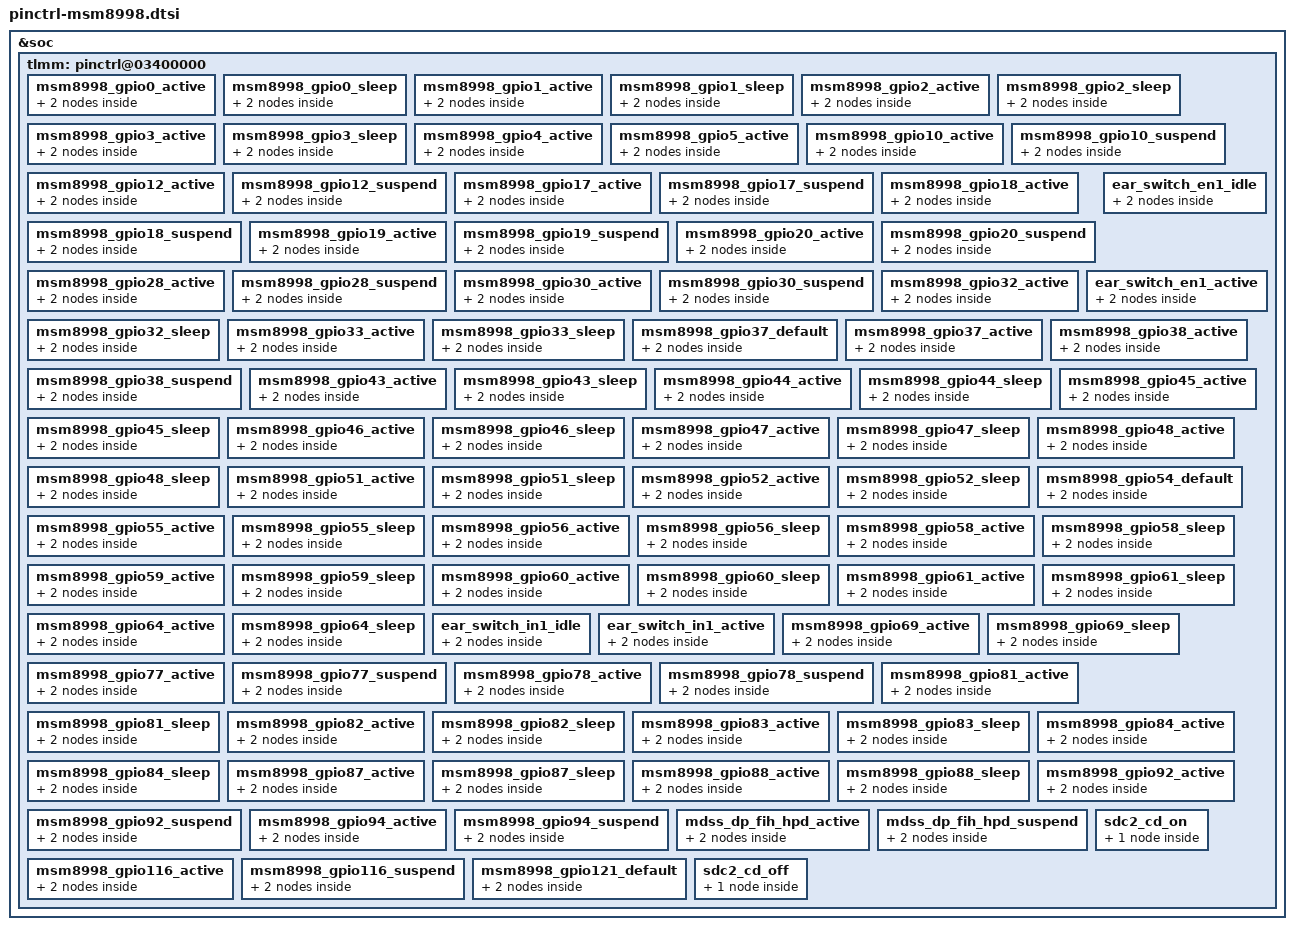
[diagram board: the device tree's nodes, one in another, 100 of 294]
/* Copyright (c) 2015-2016, The Linux Foundation. All rights reserved.
 *
 * This program is free software; you can redistribute it and/or modify
 * it under the terms of the GNU General Public License version 2 and
 * only version 2 as published by the Free Software Foundation.
 *
 * This program is distributed in the hope that it will be useful,
 * but WITHOUT ANY WARRANTY; without even the implied warranty of
 * MERCHANTABILITY or FITNESS FOR A PARTICULAR PURPOSE.  See the
 * GNU General Public License for more details.
 */

&soc {
	tlmm: pinctrl@03400000 {
		/* gpio 0 */ /* NFC_ESE_SPI_MOSI */
		msm8998_gpio0_active: msm8998_gpio0_active {
			mux {
				pins = "gpio0";
				function = "blsp_spi1";
			};

			config {
				pins = "gpio0";
				drive-strength = <6>;
				bias-disable;
			};
		};

		msm8998_gpio0_sleep: msm8998_gpio0_sleep {
			mux {
				pins = "gpio0";
				function = "blsp_spi1";
			};

			config {
				pins = "gpio0";
				drive-strength = <6>;
				bias-disable;
			};
		};

		/* gpio 1 */ /* NFC_ESE_SPI_MISO */
		msm8998_gpio1_active: msm8998_gpio1_active {
			mux {
				pins = "gpio1";
				function = "blsp_spi1";
			};

			config {
				pins = "gpio1";
				drive-strength = <6>;
				bias-disable;
			};
		};

		msm8998_gpio1_sleep: msm8998_gpio1_sleep {
			mux {
				pins = "gpio1";
				function = "blsp_spi1";
			};

			config {
				pins = "gpio1";
				drive-strength = <6>;
				bias-disable;
			};
		};

		/* gpio 2 */ /* NFC_ESE_SPI_CS_N */
		msm8998_gpio2_active: msm8998_gpio2_active {
			mux {
				pins = "gpio2";
				function = "blsp_spi1";
			};

			config {
				pins = "gpio2";
				drive-strength = <6>;
				bias-disable;
			};
		};

		msm8998_gpio2_sleep: msm8998_gpio2_sleep {
			mux {
				pins = "gpio2";
				function = "blsp_spi1";
			};

			config {
				pins = "gpio2";
				drive-strength = <6>;
				bias-disable;
			};
		};

		/* gpio 3 */ /* NFC_ESE_SPI_CLK */
		msm8998_gpio3_active: msm8998_gpio3_active {
			mux {
				pins = "gpio3";
				function = "blsp_spi1";
			};

			config {
				pins = "gpio3";
				drive-strength = <6>;
				bias-disable;
			};
		};

		msm8998_gpio3_sleep: msm8998_gpio3_sleep {
			mux {
				pins = "gpio3";
				function = "blsp_spi1";
			};

			config {
				pins = "gpio3";
				drive-strength = <6>;
				bias-disable;
			};
		};

		/* gpio 4 */ /* DEBUG_UART_TX */
		msm8998_gpio4_active: msm8998_gpio4_active {
			mux {
				pins = "gpio4";
				function = "blsp_uart8_a";
			};

			config {
				pins = "gpio4";
				drive-strength = <2>;
				bias-disable;
			};
		};

		/* gpio 5 */ /* DEBUG_UART_RX */
		msm8998_gpio5_active: msm8998_gpio5_active {
			mux {
				pins = "gpio5";
				function = "blsp_uart8_a";
			};

			config {
				pins = "gpio5";
				drive-strength = <2>;
				bias-disable;
			};
		};

		/* gpio 10 */ /* MDP_VSYNC_P */
		msm8998_gpio10_active: msm8998_gpio10_active {
			mux {
				pins = "gpio10";
				function = "mdp_vsync_a";
			};

			config {
				pins = "gpio10";
				drive-strength = <2>;
				bias-pull-down;
			};
		};

		msm8998_gpio10_suspend: msm8998_gpio10_suspend {
			mux {
				pins = "gpio10";
				function = "mdp_vsync_a";
			};

			config {
				pins = "gpio10";
				drive-strength = <2>;
				bias-pull-down;
			};
		};

		/* gpio 12 */ /* NFC_ENABLE */
		msm8998_gpio12_active: msm8998_gpio12_active {
			mux {
				pins = "gpio12";
				function = "gpio";
			};

			config {
				pins = "gpio12";
				drive-strength = <6>;
				bias-pull-up;
			};
		};

		msm8998_gpio12_suspend: msm8998_gpio12_suspend {
			mux {
				pins = "gpio12";
				function = "gpio";
			};

			config {
				pins = "gpio12";
				drive-strength = <6>;
				bias-disable;
			};
		};

		/* gpio 17 */ /* CCI_I2C_SDA0 */
		msm8998_gpio17_active: msm8998_gpio17_active {
			mux {
				pins = "gpio17";
				function = "cci_i2c";
			};

			config {
				pins = "gpio17";
				drive-strength = <2>;
				bias-pull-up;
			};
		};

		msm8998_gpio17_suspend: msm8998_gpio17_suspend {
			mux {
				pins = "gpio17";
				function = "cci_i2c";
		};

			config {
				pins = "gpio17";
				drive-strength = <2>;
				bias-disable; /* No PULL */
			};
		};

		/* gpio 18 */ /* CCI_I2C_SCL0 */
		msm8998_gpio18_active: msm8998_gpio18_active {
			mux {
				pins = "gpio18";
				function = "cci_i2c";
			};

			config {
				pins = "gpio18";
				drive-strength = <2>;
				bias-pull-up;
			};
		};

		msm8998_gpio18_suspend: msm8998_gpio18_suspend {
			mux {
				pins = "gpio18";
				function = "cci_i2c";
		};

			config {
				pins = "gpio18";
				drive-strength = <2>;
				bias-disable; /* No PULL */
			};
		};

		/* gpio 19 */ /* CCI_I2C_SDA1 */
		msm8998_gpio19_active: msm8998_gpio19_active {
			mux {
				pins = "gpio19";
				function = "cci_i2c";
			};

			config {
				pins = "gpio19";
				drive-strength = <2>;
				bias-pull-up;
			};
		};

		msm8998_gpio19_suspend: msm8998_gpio19_suspend {
			mux {
				pins = "gpio19";
				function = "cci_i2c";
			};

			config {
				pins = "gpio19";
				drive-strength = <2>;
				bias-disable; /* No PULL */
			};
		};

		/* gpio 20 */ /* CCI_I2C_SCL1 */
		msm8998_gpio20_active: msm8998_gpio20_active {
			mux {
				pins = "gpio20";
				function = "cci_i2c";
			};

			config {
				pins = "gpio20";
				drive-strength = <2>;
				bias-pull-up;
			};
		};

		msm8998_gpio20_suspend: msm8998_gpio20_suspend {
			mux {
				pins = "gpio20";
				function = "cci_i2c";
			};

			config {
				pins = "gpio20";
				drive-strength = <2>;
				bias-disable; /* No PULL */
			};
		};

		/* gpio 28 */ /* RCAM1_VCA_EN */
		msm8998_gpio28_active: msm8998_gpio28_active {
			mux {
				pins = "gpio28";
				function = "gpio";
			};

			config {
				pins = "gpio28";
				drive-strength = <2>;
				bias-disable;
			};
		};

		msm8998_gpio28_suspend: msm8998_gpio28_suspend {
			mux {
				pins = "gpio28";
				function = "gpio";
			};

			config {
				pins = "gpio28";
				drive-strength = <2>;
				bias-pull-down;
			};
		};

		/* gpio 30 */ /* RCAM2_VCA_EN */
		msm8998_gpio30_active: msm8998_gpio30_active {
			mux {
				pins = "gpio30";
				function = "gpio";
			};

			config {
				pins = "gpio30";
				drive-strength = <2>;
				bias-disable;
			};
		};

		msm8998_gpio30_suspend: msm8998_gpio30_suspend {
			mux {
				pins = "gpio30";
				function = "gpio";
			};

			config {
				pins = "gpio30";
				drive-strength = <2>;
				bias-pull-down;
			};
		};

		/* gpio 32 */ /* RANGING_SCL */
		msm8998_gpio32_active: msm8998_gpio32_active {
			mux {
				pins = "gpio32";
				function = "blsp_i2c2";
			};

			config {
				pins = "gpio32";
				drive-strength = <2>;
				bias-disable;
			};
		};

		msm8998_gpio32_sleep: msm8998_gpio32_sleep {
			mux {
				pins = "gpio32";
				function = "blsp_i2c2";
			};

			config {
				pins = "gpio32";
				drive-strength = <2>;
				bias-pull-up;
			};
		};

		/* gpio 33 */ /* RANGING_SDA */
		msm8998_gpio33_active: msm8998_gpio33_active {
			mux {
				pins = "gpio33";
				function = "blsp_i2c2";
			};

			config {
				pins = "gpio33";
				drive-strength = <2>;
				bias-disable;
			};
		};

		msm8998_gpio33_sleep: msm8998_gpio33_sleep {
			mux {
				pins = "gpio33";
				function = "blsp_i2c2";
			};

			config {
				pins = "gpio33";
				drive-strength = <2>;
				bias-pull-up;
			};
		};

		/* gpio 35 */ /* AUDIO_SW_EN */
		ear_switch_en1_idle: ear_switch_en1_idle {
			mux {
				pins = "gpio35";
				function = "gpio";
			};
			config {
				pins = "gpio35";
				drive-strength = <2>;
				bias-pull-down;
				output-low;
			};
		};

		ear_switch_en1_active: ear_switch_en1_active {
			mux {
				pins = "gpio35";
				function = "gpio";
			};
			config {
				pins = "gpio35";
				drive-strength = <2>;
				bias-disable;
				output-high;
			};
		};

		/* gpio 37 */ /* KS_BRI_PCIE_WAKE_N */
		msm8998_gpio37_default: msm8998_gpio37_default {
			mux {
				pins = "gpio37";
				function = "gpio";
			};

			config {
				pins = "gpio37";
				drive-strength = <2>;
				bias-disable;
			};
		};

		msm8998_gpio37_active: msm8998_gpio37_active {
			mux {
				pins = "gpio37";
				function = "gpio";
			};

			config {
				pins = "gpio37";
				drive-strength = <2>;
				bias-disable;
				output-high;
			};
		};

		/* gpio 38 */ /* CC_DIR */
		msm8998_gpio38_active: msm8998_gpio38_active {
			mux {
				pins = "gpio38";
				function = "gpio";
			};

			config {
				pins = "gpio38";
				drive-strength = <16>;
				bias-disable;
			};
		};

		msm8998_gpio38_suspend: msm8998_gpio38_suspend {
			mux {
				pins = "gpio38";
				function = "gpio";
			};

			config {
				pins = "gpio38";
				drive-strength = <2>;
				bias-pull-down;
			};
		};

		/* gpio 43 */ /* NFC_I2C_SDA */
		msm8998_gpio43_active: msm8998_gpio43_active {
			mux {
				pins = "gpio43";
				function = "blsp_i2c6";
			};

			config {
				pins = "gpio43";
				drive-strength = <2>;
				bias-disable;
			};
		};

		msm8998_gpio43_sleep: msm8998_gpio43_sleep {
			mux {
				pins = "gpio43";
				function = "blsp_i2c6";
			};

			config {
				pins = "gpio43";
				drive-strength = <2>;
				bias-pull-up;
			};
		};

		/* gpio 44 */ /* NFC_I2C_CLK */
		msm8998_gpio44_active: msm8998_gpio44_active {
			mux {
				pins = "gpio44";
				function = "blsp_i2c6";
			};

			config {
				pins = "gpio44";
				drive-strength = <2>;
				bias-disable;
			};
		};

		msm8998_gpio44_sleep: msm8998_gpio44_sleep {
			mux {
				pins = "gpio44";
				function = "blsp_i2c6";
			};

			config {
				pins = "gpio44";
				drive-strength = <2>;
				bias-pull-up;
			};
		};

		/* gpio 45 */ /* BT_HCI_UART_TXD */
		msm8998_gpio45_active: msm8998_gpio45_active {
			mux {
				pins = "gpio45";
				function = "blsp_uart3_a";
			};

			config {
				pins = "gpio45";
				drive-strength = <2>;
				bias-disable;
			};
		};

		msm8998_gpio45_sleep: msm8998_gpio45_sleep {
			mux {
				pins = "gpio45";
				function = "gpio";
			};

			config {
				pins = "gpio45";
				drive-strength = <2>;
				bias-pull-up;
			};
		};

		/* gpio 46 */ /* BT_HCI_UART_RXD */
		msm8998_gpio46_active: msm8998_gpio46_active {
			mux {
				pins = "gpio46";
				function = "blsp_uart3_a";
			};

			config {
				pins = "gpio46";
				drive-strength = <2>;
				bias-disable;
			};
		};

		msm8998_gpio46_sleep: msm8998_gpio46_sleep {
			mux {
				pins = "gpio46";
				function = "gpio";
			};

			config {
				pins = "gpio46";
				drive-strength = <2>;
				bias-pull-up;
			};
		};

		/* gpio 47 */ /* BT_HCI_UART_CTS_N */
		msm8998_gpio47_active: msm8998_gpio47_active {
			mux {
				pins = "gpio47";
				function = "blsp_uart3_a";
			};

			config {
				pins = "gpio47";
				drive-strength = <2>;
				bias-disable;
			};
		};

		msm8998_gpio47_sleep: msm8998_gpio47_sleep {
			mux {
				pins = "gpio47";
				function = "gpio";
			};

			config {
				pins = "gpio47";
				drive-strength = <2>;
				bias-pull-up;
			};
		};

		/* gpio 48 */ /* BT_HCI_UART_RFR_N */
		msm8998_gpio48_active: msm8998_gpio48_active {
			mux {
				pins = "gpio48";
				function = "blsp_uart3_a";
			};

			config {
				pins = "gpio48";
				drive-strength = <2>;
				bias-disable;
			};
		};

		msm8998_gpio48_sleep: msm8998_gpio48_sleep {
			mux {
				pins = "gpio48";
				function = "gpio";
			};

			config {
				pins = "gpio48";
				drive-strength = <2>;
				bias-pull-up;
			};
		};

		/* gpio 51 */ /* SMART_AMP_DAT */
		msm8998_gpio51_active: msm8998_gpio51_active {
			mux {
				pins = "gpio51";
				function = "blsp_i2c9";
			};

			config {
				pins = "gpio51";
				drive-strength = <2>;
				bias-disable;
			};
		};

		msm8998_gpio51_sleep: msm8998_gpio51_sleep {
			mux {
				pins = "gpio51";
				function = "blsp_i2c9";
			};

			config {
				pins = "gpio51";
				drive-strength = <2>;
				bias-disable;
			};
		};

		/* gpio 52 */ /* SMART_AMP_SCL */
		msm8998_gpio52_active: msm8998_gpio52_active {
			mux {
				pins = "gpio52";
				function = "blsp_i2c9";
			};

			config {
				pins = "gpio52";
				drive-strength = <2>;
				bias-disable;
			};
		};

		msm8998_gpio52_sleep: msm8998_gpio52_sleep {
			mux {
				pins = "gpio52";
				function = "blsp_i2c9";
			};

			config {
				pins = "gpio52";
				drive-strength = <2>;
				bias-disable;
			};
		};

		/* gpio 54 */ /* CODEC_INT1 */
		msm8998_gpio54_default: msm8998_gpio54_default{
			mux {
				pins = "gpio54";
				function = "gpio";
			};

			config {
				pins = "gpio54";
				drive-strength = <2>;
				bias-disable;
				input-enable;
			};
		};

		/* gpio 55 */ /* FP_APPS_I2C_SDA */
		msm8998_gpio55_active: msm8998_gpio55_active {
			mux {
				pins = "gpio55";
				function = "blsp_i2c7";
			};

			config {
				pins = "gpio55";
				drive-strength = <2>;
				bias-disable;
			};
		};

		msm8998_gpio55_sleep: msm8998_gpio55_sleep {
			mux {
				pins = "gpio55";
				function = "blsp_i2c7";
			};

			config {
				pins = "gpio55";
				drive-strength = <2>;
				bias-pull-up;
			};
		};

		/* gpio 56 */ /* FP_APPS_I2C7_SCL */
		msm8998_gpio56_active: msm8998_gpio56_active {
			mux {
				pins = "gpio56";
				function = "blsp_i2c7";
			};

			config {
				pins = "gpio56";
				drive-strength = <2>;
				bias-disable;
			};
		};

		msm8998_gpio56_sleep: msm8998_gpio56_sleep {
			mux {
				pins = "gpio56";
				function = "blsp_i2c7";
			};

			config {
				pins = "gpio56";
				drive-strength = <2>;
				bias-pull-up;
			};
		};

		/* gpio 58 */ /* CDC_TX_I2S_SCK */
		msm8998_gpio58_active: msm8998_gpio58_active {
			mux {
				pins = "gpio58";
				function = "qua_mi2s";
			};

			config {
				pins = "gpio58";
				drive-strength = <8>;
				bias-disable;
				output-high;
			};
		};

		msm8998_gpio58_sleep: msm8998_gpio58_sleep {
			mux {
				pins = "gpio58";
				function = "qua_mi2s";
			};

			config {
				pins = "gpio58";
				drive-strength = <2>;
				bias-pull-down;
			};
		};

		/* gpio 59 */ /* CDC_TX_I2S_WS */
		msm8998_gpio59_active: msm8998_gpio59_active {
			mux {
				pins = "gpio59";
				function = "qua_mi2s";
			};

			config {
				pins = "gpio59";
				drive-strength = <8>;
				bias-disable;
				output-high;
			};
		};

		msm8998_gpio59_sleep: msm8998_gpio59_sleep {
			mux {
				pins = "gpio59";
				function = "qua_mi2s";
			};

			config {
				pins = "gpio59";
				drive-strength = <2>;
				bias-pull-down;
			};
		};

		/* gpio 60 */ /* CDC_TX_I2S_DI */
		msm8998_gpio60_active: msm8998_gpio60_active {
			mux {
				pins = "gpio60";
				function = "qua_mi2s";
			};

			config {
				pins = "gpio60";
				drive-strength = <8>;
				bias-disable;
			};
		};

		msm8998_gpio60_sleep: msm8998_gpio60_sleep {
			mux {
				pins = "gpio60";
				function = "qua_mi2s";
			};

			config {
				pins = "gpio60";
				drive-strength = <2>;
				bias-pull-down;
			};
		};

		/* gpio 61 */ /* CDC_TX_I2S_DO */
		msm8998_gpio61_active: msm8998_gpio61_active {
			mux {
				pins = "gpio61";
				function = "qua_mi2s";
			};

			config {
				pins = "gpio61";
				drive-strength = <8>;
				bias-disable;
				input-enable;
			};
		};

		msm8998_gpio61_sleep: msm8998_gpio61_sleep {
			mux {
				pins = "gpio61";
				function = "qua_mi2s";
			};

			config {
				pins = "gpio61";
				drive-strength = <2>;
				bias-pull-down;
			};
		};

		/* gpio 64 */ /* CODEC_RST_N */
		msm8998_gpio64_active:msm8998_gpio64_active {
			mux {
				pins = "gpio64";
				function = "gpio";
			};
			config {
				pins = "gpio64";
				drive-strength = <2>;
				bias-disable;
				output-high;
			};
		};

		msm8998_gpio64_sleep: msm8998_gpio64_sleep {
			mux {
				pins = "gpio64";
				function = "gpio";
			};
			config {
				pins = "gpio64";
				drive-strength = <2>;
				bias-disable;
				output-low;
			};
		};

		/* gpio 66 */ /* AUDIO_SW_IN */
		ear_switch_in1_idle: ear_switch_in1_idle {
			mux {
				pins = "gpio66";
				function = "gpio";
			};
			config {
				pins = "gpio66";
				drive-strength = <2>;
				bias-pull-down;
				output-low;
			};
		};

		ear_switch_in1_active: ear_switch_in1_active {
			mux {
				pins = "gpio66";
				function = "gpio";
			};
			config {
				pins = "gpio66";
				drive-strength = <2>;
				bias-disable;
				output-high;
			};
		};

		/* gpio 69 */ /* SPKR_I2S_CLK */
		msm8998_gpio69_active: msm8998_gpio69_active {
			mux {
				pins = "gpio69";
				function = "spkr_i2s";
			};

			config {
				pins = "gpio69";
				drive-strength = <8>;
				bias-disable;
			};
		};

		msm8998_gpio69_sleep: msm8998_gpio69_sleep {
			mux {
				pins = "gpio69";
				function = "spkr_i2s";
			};

			config {
				pins = "gpio69";
				drive-strength = <2>;
				bias-pull-down;
			};
		};

		/* gpio 77 */ /* SBU_SW_OE */
		msm8998_gpio77_active: msm8998_gpio77_active {
			mux {
				pins = "gpio77";
				function = "gpio";
			};

			config {
				pins = "gpio77";
				drive-strength = <8>;
				bias-disable;
			};
		};

		msm8998_gpio77_suspend: msm8998_gpio77_suspend {
			mux {
				pins = "gpio77";
				function = "gpio";
			};

			config {
				pins = "gpio77";
				drive-strength = <2>;
				bias-pull-down;
			};
		};

		/* gpio 78 */ /* SBU_SW_SEL */
		msm8998_gpio78_active: msm8998_gpio78_active {
			mux {
				pins = "gpio78";
				function = "gpio";
			};

			config {
				pins = "gpio78";
				drive-strength = <8>;
				bias-disable;
			};
		};

		msm8998_gpio78_suspend: msm8998_gpio78_suspend {
			mux {
				pins = "gpio78";
				function = "gpio";
			};

			config {
				pins = "gpio78";
				drive-strength = <2>;
				bias-pull-down;
			};
		};

		/* gpio 81 */ /* BLSP_SPI_2_MOSI */
		msm8998_gpio81_active: msm8998_gpio81_active {
			mux {
				pins = "gpio81";
				function = "blsp_spi12";
			};

			config {
				pins = "gpio81";
				drive-strength = <6>;
				bias-disable;
			};
		};

		msm8998_gpio81_sleep: msm8998_gpio81_sleep {
			mux {
				pins = "gpio81";
				function = "blsp_spi12";
			};

			config {
				pins = "gpio81";
				drive-strength = <6>;
				bias-disable;
			};
		};

		/* gpio 82 */ /* BLSP_SPI_2_MISO */
		msm8998_gpio82_active: msm8998_gpio82_active {
			mux {
				pins = "gpio82";
				function = "blsp_spi12";
			};

			config {
				pins = "gpio82";
				drive-strength = <6>;
				bias-disable;
			};
		};

		msm8998_gpio82_sleep: msm8998_gpio82_sleep {
			mux {
				pins = "gpio82";
				function = "blsp_spi12";
			};

			config {
				pins = "gpio82";
				drive-strength = <6>;
				bias-disable;
			};
		};

		/* gpio 83 */ /* BLSP_SPI_2_CS_N */
		msm8998_gpio83_active: msm8998_gpio83_active {
			mux {
				pins = "gpio83";
				function = "blsp_spi12";
			};

			config {
				pins = "gpio83";
				drive-strength = <6>;
				bias-disable;
			};
		};

		msm8998_gpio83_sleep: msm8998_gpio83_sleep {
			mux {
				pins = "gpio83";
				function = "blsp_spi12";
			};

			config {
				pins = "gpio83";
				drive-strength = <6>;
				bias-disable;
			};
		};

		/* gpio 84 */ /* BLSP_SPI_2_CLK */
		msm8998_gpio84_active: msm8998_gpio84_active {
			mux {
				pins = "gpio84";
				function = "blsp_spi12";
			};

			config {
				pins = "gpio84";
				drive-strength = <6>;
				bias-disable;
			};
		};

		msm8998_gpio84_sleep: msm8998_gpio84_sleep {
			mux {
				pins = "gpio84";
				function = "blsp_spi12";
			};

			config {
				pins = "gpio84";
				drive-strength = <6>;
				bias-disable;
			};
		};

		/* gpio 87 */ /* BLSP_SPI_CS_N5 */
		msm8998_gpio87_active: msm8998_gpio87_active {
			mux {
				pins = "gpio87";
				function = "blsp_i2c5";
			};

			config {
				pins = "gpio87";
				drive-strength = <6>;
				bias-disable;
			};
		};

		msm8998_gpio87_sleep: msm8998_gpio87_sleep {
			mux {
				pins = "gpio87";
				function = "blsp_i2c5";
			};

			config {
				pins = "gpio87";
				drive-strength = <6>;
				bias-disable;
			};
		};

		/* gpio 88 */ /* BLSP_SPI_CLK5 */
		msm8998_gpio88_active: msm8998_gpio88_active {
			mux {
				pins = "gpio88";
				function = "blsp_i2c5";
			};

			config {
				pins = "gpio88";
				drive-strength = <6>;
				bias-disable;
			};
		};

		msm8998_gpio88_sleep: msm8998_gpio88_sleep {
			mux {
				pins = "gpio88";
				function = "blsp_i2c5";
			};

			config {
				pins = "gpio88";
				drive-strength = <6>;
				bias-disable;
			};
		};

		/* gpio 92 */ /* NFC_INT_IRQ */
		msm8998_gpio92_active: msm8998_gpio92_active {
			mux {
				pins = "gpio92";
				function = "gpio";
			};

			config {
				pins = "gpio92";
				drive-strength = <6>;
				bias-pull-up;
			};
		};

		msm8998_gpio92_suspend: msm8998_gpio92_suspend {
			mux {
				pins = "gpio92";
				function = "gpio";
			};

			config {
				pins = "gpio92";
				drive-strength = <6>;
				bias-pull-up;
			};
		};

		/* gpio 94 */ /* LCD0_RESET_N */
		msm8998_gpio94_active: msm8998_gpio94_active {
			mux {
				pins = "gpio94";
				function = "gpio";
			};

			config {
				pins = "gpio94";
				drive-strength = <8>;
				bias-disable;
			};
		};

		msm8998_gpio94_suspend: msm8998_gpio94_suspend {
			mux {
				pins = "gpio94";
				function = "gpio";
			};

			config {
				pins = "gpio94";
				drive-strength = <2>;
				bias-pull-down;
			};
		};

		mdss_dp_fih_hpd_active: mdss_dp_fih_hpd_active {
			mux {
				pins = "gpio115";
				function = "gpio";
			};

			config {
				pins = "gpio115";
				bias-disable;
				drive-strength = <16>;
				output-low;
			};
		};

		mdss_dp_fih_hpd_suspend: mdss_dp_fih_hpd_suspend {
			mux {
				pins = "gpio115";
				function = "gpio";
			};

			config {
				pins = "gpio115";
				bias-pull-down;
				drive-strength = <2>;
			};
		};

		/* gpio 116 */ /* NFC_ESE_PWR_REQ */
		msm8998_gpio116_active: msm8998_gpio116_active {
			mux {
				pins = "gpio116";
				function = "gpio";
			};

			config {
				pins = "gpio116";
				drive-strength = <6>;
				bias-pull-up;
			};
		};

		msm8998_gpio116_suspend: msm8998_gpio116_suspend {
			mux {
				pins = "gpio116";
				function = "gpio";
			};

			config {
				pins = "gpio116";
				drive-strength = <6>;
				bias-disable;
			};
		};

		/* gpio 121 */ /* FP_INT_N */
		msm8998_gpio121_default: msm8998_gpio121_default {
			mux {
				pins = "gpio121";
				function = "gpio";
			};

			config {
				pins = "gpio121";
				drive-strength = <2>;
				bias-disable;
				input-enable;
			};
		};

		sdc2_cd_on: sdc2_cd_on {
			config {
				bias-disable;           /* no pull */
			};
		};

		sdc2_cd_off: sdc2_cd_off {
			config {
				bias-disable;           /* no pull */
			};
		};
	};
};
